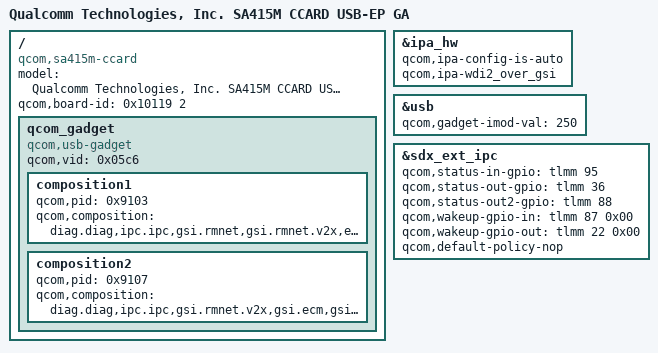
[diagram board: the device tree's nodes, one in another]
/* Copyright (c) 2021, The Linux Foundation. All rights reserved.
 *
 * This program is free software; you can redistribute it and/or modify
 * it under the terms of the GNU General Public License version 2 and
 * only version 2 as published by the Free Software Foundation.
 *
 * This program is distributed in the hope that it will be useful,
 * but WITHOUT ANY WARRANTY; without even the implied warranty of
 * MERCHANTABILITY or FITNESS FOR A PARTICULAR PURPOSE.  See the
 * GNU General Public License for more details.
 */

/dts-v1/;

#include "sa415m-ccard.dtsi"

/ {
	model = "Qualcomm Technologies, Inc. SA415M CCARD USB-EP GA";
	compatible = "qcom,sa415m-ccard",
		"qcom,sdxpoorwills", "qcom,ccard";
	qcom,board-id = <0x10119 2>;

	qcom_gadget {
		compatible = "qcom,usb-gadget";
		qcom,vid = <0x05c6>;

		composition1 {
			qcom,pid = <0x9103>;
			qcom,composition = "diag.diag,ipc.ipc,gsi.rmnet,gsi.rmnet.v2x,ecm.ecm,gsi.dpl";
		};

		composition2 {
			qcom,pid = <0x9107>;
			qcom,composition = "diag.diag,ipc.ipc,gsi.rmnet.v2x,gsi.ecm,gsi.dpl";
		};
	};
};

&ipa_hw {
	qcom,ipa-config-is-auto;
	qcom,ipa-wdi2_over_gsi;
};

&usb {
	qcom,gadget-imod-val = <250>;
};

&sdx_ext_ipc {
	qcom,status-in-gpio = <&tlmm 95 0x00>;
	qcom,status-out-gpio = <&tlmm 36 0x00>;
	qcom,status-out2-gpio = <&tlmm 88 0x00>;
	qcom,wakeup-gpio-in = <&tlmm 87 0x00>;
	qcom,wakeup-gpio-out = <&tlmm 22 0x00>;
	qcom,default-policy-nop;
	status = "okay";
};
